# SOC_ADC register map
Vendor: Texas Instruments
Peripheral module from a debugger description file (folder cc2538).
Registers are 32-bit, access per field, no defined reset value unless marked. A register's access mark holds for its fields unless they carry their own. Offsets are as the file gives them; lines under a group give offsets from that group; [hi:lo] are bit positions; {n}, {i} and the like mark numbered series; 'fields as' and 'values as' point back to an identical list; <NAME> marks a mode.

## SOC_ADC — Register fields should be considered static unless otherwise noted as dynamic.
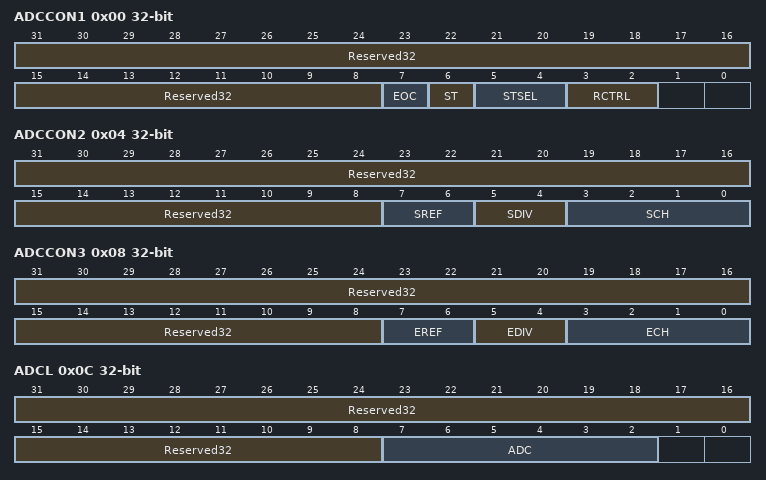
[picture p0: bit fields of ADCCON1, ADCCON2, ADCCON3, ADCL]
0x00 ADCCON1 — This register controls the ADC.
  [31:8] Reserved32 ro — This register is 8 bits in a 32-bit address space.
  [7] EOC rw — End of conversion. Cleared when ADCH has been read. If a new conversion is completed before the previous data has been read, the EOC bit remains high. 0: Conversion not complete 1: Conversion completed
  [6] ST rw — Start conversion Read as 1 until conversion completes 0: No conversion in progress. 1: Start a conversion sequence if ADCCON1.STSEL = 11 and no sequence is running.
  [5:4] STSEL rw — Start select Selects the event that starts a new conversion sequence 00: Not implemented 01: Full speed. Do not wait for triggers 10: Timer 1 channel 0 compare event 11: ADCCON1.ST = 1
  [3:2] RCTRL rw — Controls the 16-bit random-number generator (see User Guide Chapter 16) When 01 is written, the setting automatically returns to 00 when the operation completes. 00: Normal operation (13x unrolling) 01: Clock the LFSR once (13x unrolling) 10: Reserved 11: Stopped. The random-number generator is turned off.
0x04 ADCCON2 — This register controls the ADC.
  [31:8] Reserved32 ro — This register is 8 bits in a 32-bit address space.
  [7:6] SREF rw — Selects reference voltage used for the sequence of conversions 00: Internal reference 01: External reference on AIN7 pin 10: AVDD5 pin 11: External reference on AIN6-AIN7 differential input
  [5:4] SDIV rw — Sets the decimation rate for channels included in the sequence of conversions. The decimation rate also determines the resolution and time required to complete a conversion. 00: 64 decimation rate (7 bits ENOB setting) 01: 128 decimation rate (9 bits ENOB setting) 10: 256 decimation rate (10 bits ENOB setting) 11: 512 decimation rate (12 bits ENOB setting)
  [3:0] SCH rw — Sequence channel select Selects the end of the sequence A sequence can either be from AIN0 to AIN7 (SCH <= 7) or from differential input AIN0-AIN1 to AIN6-AIN7 (8 <= SCH <= 11). For other settings, only one conversions is performed. When read, these bits indicate the channel number on which a conversion is ongoing: 0000: AIN0 0001: AIN1 0010: AIN2 0011: AIN3 0100: AIN4 0101: AIN5 0110: AIN6 0111: AIN7 1000: AIN0-AIN1 1001: AIN2-AIN3 1010: AIN4-AIN5 1011: AIN6-AIN7 1100: GND 1101: Reserved 1110: Temperature sensor 1111: VDD/3
0x08 ADCCON3 — This register controls the ADC.
  [31:8] Reserved32 ro — This register is 8 bits in a 32-bit address space.
  [7:6] EREF rw — Selects reference voltage used for the extra conversion 00: Internal reference 01: External reference on AIN7 pin 10: AVDD5 pin 11: External reference on AIN6-AIN7 differential input
  [5:4] EDIV rw — Sets the decimation rate used for the extra conversion The decimation rate also determines the resolution and the time required to complete the conversion. 00: 64 decimation rate (7 bits ENOB) 01: 128 decimation rate (9 bits ENOB) 10: 256 decimation rate (10 bits ENOB) 11: 512 decimation rate (12 bits ENOB)
  [3:0] ECH rw — Single channel select. Selects the channel number of the single conversion that is triggered by writing to ADCCON3. 0000: AIN0 0001: AIN1 0010: AIN2 0011: AIN3 0100: AIN4 0101: AIN5 0110: AIN6 0111: AIN7 1000: AIN0-AIN1 1001: AIN2-AIN3 1010: AIN4-AIN5 1011: AIN6-AIN7 1100: GND 1101: Reserved 1110: Temperature sensor 1111: VDD/3
0x0C ADCL ro — This register contains the least-significant part of ADC conversion result.
  [31:8] Reserved32 — This register is 8 bits in a 32-bit address space.
  [7:2] ADC — Least-significant part of ADC conversion result
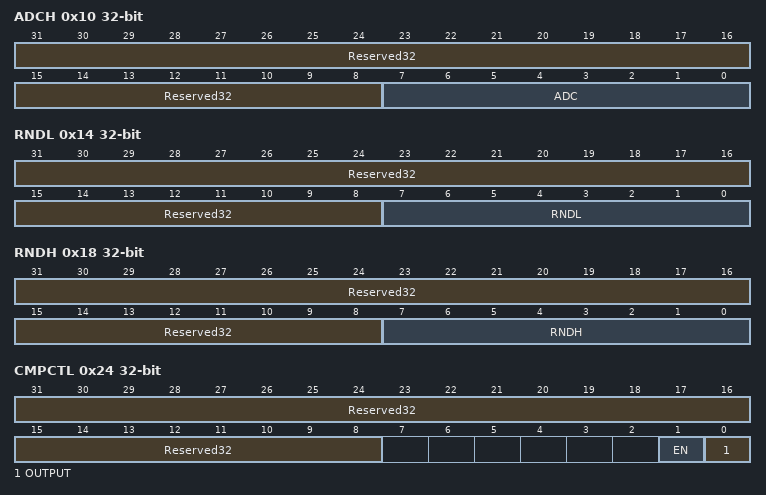
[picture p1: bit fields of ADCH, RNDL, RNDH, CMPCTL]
0x10 ADCH ro — This register contains the most-significant part of ADC conversion result.
  [31:8] Reserved32 — This register is 8 bits in a 32-bit address space.
  [7:0] ADC — Most-significant part of ADC conversion result
0x14 RNDL — This registers contains random-number-generator data; low byte.
  [31:8] Reserved32 ro — This register is 8 bits in a 32-bit address space.
  [7:0] RNDL rw — Random value/seed or CRC result, low byte When used for random-number generation, writing to this register twice seeds the random-number generator. Writing to this register copies the 8 LSBs of the LFSR to the 8 MSBs and replaces the 8 LSBs with the data value written. The value returned when reading from this register is the 8 LSBs of the LFSR. When used for random-number generation, reading this register returns the 8 LSBs of the random number. When used for CRC calculations, reading this register returns the 8 LSBs of the CRC result.
0x18 RNDH — This register contains random-number-generator data; high byte.
  [31:8] Reserved32 ro — This register is 8 bits in a 32-bit address space.
  [7:0] RNDH rw — Random value or CRC result/input data, high byte When written, a CRC16 calculation is triggered, and the data value written is processed starting with the MSB. The value returned when reading from this register is the 8 MSBs of the LFSR. When used for random-number generation, reading this register returns the 8 MSBs of the random number. When used for CRC calculations, reading this register returns the 8 MSBs of the CRC result.
0x24 CMPCTL — Analog comparator control and status register.
  [31:8] Reserved32 ro — This register is 8 bits in a 32-bit address space.
  [1] EN rw — Comparator enable
  [0] OUTPUT ro — Comparator output
